# CONTROLSS_GLOBAL_CTRL_CONTROLSS_CTRL_502F0000h register map
Vendor: Texas Instruments
Peripheral module from a debugger description file (folder AM261x).
Registers are 32-bit, read-write, reset 0x0 unless marked. A register's access mark holds for its fields unless they carry their own. Offsets are as the file gives them; lines under a group give offsets from that group; [hi:lo] are bit positions; {n}, {i} and the like mark numbered series; 'fields as' and 'values as' point back to an identical list; <NAME> marks a mode.

## CONTROLSS_CTRL
{0x4+4i} CONTROLSS_CTRL_ADCEXTCHXBAR{i}_G0_SEL (i=0..9) — ADC EXTCH XBAR [x] Input Select.
  [3:0] ADCEXTCHXBAR{i}_G0_SEL_SEL — ADC EXTCH XBAR {i} Input Select0h ADC0 ADCCHSEL01h ADC0 ADCCHSEL12h ADC0 ADCCHSEL23h ADC0 ADCCHSEL34h ADC1 ADCCHSEL05h ADC1 ADCCHSEL16h ADC1 ADCCHSEL27h ADC1 ADCCHSEL38h ADC2 ADCCHSEL09h ADC2 ADCCHSEL1Ah: ADC2 ADCCHSEL2Bh: ADC2 ADCCHSEL3Example: ADC2EXTCHSEL_BIT0 needs to be connect to ADC_EXTCH_XBAROUT3, then ADCEXTCHXBAR3.G0.SEL set to 4'b1000
0x44 CONTROLSS_CTRL_ADCSOCFRCGBSEL — ADC Global SoC Force select.
  [2:0] ADCSOCFRCGBSEL_ENABLE — ADCSOCFRCGBSEL has one bit for each ADCBIT FIELD Descriptionbitx ADCx Indicate if ADCx selected for global SW trigger 1'b0 Not selected for Global SW Trigger 1'b1 Selected for Global SW TriggerReset Reset type: SYSRSnNote: x represents 0-2
0x48 CONTROLSS_CTRL_ADCSOCFRCGB — ADC Global SOC Force.
  [15:0] ADCSOCFRCGB_TRIG — ADCSOCFRCGB has one bit for each SOC[Start of conversion]BIT FIELD Descriptionbitxx SOCxx Indicate if SOCxx selected for global SW trigger 1'b0 Not selected for Global SW Trigger 1'b1 Selected for Global SW Trigger Reset type: SYSRSnNote: xx represents 0-15
0x4C CONTROLSS_CTRL_ADC_EXTCH_DLY_SEL reset 0x1 — Mux select to choose delay for adc_extchsel.
  [2:0] ADC_EXTCH_DLY_SEL_SEL — MUX select to choose delay3'd0: 2 cycle delay3'd1: 3 cycle delay3'd2: 4 cycle delay3'd3: 5 cycle delay3'd4: 6 cycle delay
0x78 CONTROLSS_CTRL_SDFM0_CLK0_OUT_SEL — SDFM0_CLK[x]_OUT Input Select.
  [0] SDFM0_CLK0_OUT_SEL_SEL — SDFM0_CLK0_OUT Input select 1'b0: ECAP0_OUT [default] 1'b1: ECAP7_OUT
0x7C CONTROLSS_CTRL_SDFM0_CLK1_OUT_SEL — SDFM0_CLK[x]_OUT Input Select.
  [0] SDFM0_CLK1_OUT_SEL_SEL — SDFM0_CLK1OUT Input select 1'b0: ECAP1_OUT [default] 1'b1: ECAP6_OUT
0x80 CONTROLSS_CTRL_SDFM0_CLK2_OUT_SEL — SDFM0_CLK[x]_OUT Input Select.
  [0] SDFM0_CLK2_OUT_SEL_SEL — SDFM0_CLK2_OUT Input select 1'b0: ECAP2_OUT [default] 1'b1: ECAP5_OUT
0x84 CONTROLSS_CTRL_SDFM0_CLK3_OUT_SEL — SDFM0_CLK[x]_OUT Input Select.
  [0] SDFM0_CLK3_OUT_SEL_SEL — SDFM0_CLK3_OUT Input select 1'b0: ECAP3_OUT [default] 1'b1: ECAP4_OUT
0x88 CONTROLSS_CTRL_SDFM1_CLK0_OUT_SEL — SDFM1_CLK[x]_OUT Input Select.
  [0] SDFM1_CLK0_OUT_SEL_SEL — SDFM1_CLK0_OUT Input select 1'b0: ECAP4_OUT [default] 1'b1: ECAP3_OUT
0x8C CONTROLSS_CTRL_SDFM1_CLK1_OUT_SEL — SDFM1_CLK[x]_OUT Input Select.
  [0] SDFM1_CLK1_OUT_SEL_SEL — SDFM1_CLK1_OUT Input select 1'b0: ECAP5_OUT [default] 1'b1: ECAP2_OUT
0x90 CONTROLSS_CTRL_SDFM1_CLK2_OUT_SEL — SDFM1_CLK[x]_OUT Input Select.
  [0] SDFM1_CLK2_OUT_SEL_SEL — SDFM1_CLK2_OUT Input select 1'b0: ECAP6_OUT [default] 1'b1: ECAP1_OUT
0x94 CONTROLSS_CTRL_SDFM1_CLK3_OUT_SEL — SDFM1_CLK[x]_OUT Input Select.
  [0] SDFM1_CLK3_OUT_SEL_SEL — SDFM1_CLK3_OUT Input select 1'b0: ECAP7_OUT [default] 1'b1: ECAP0_OUT
0xFC CONTROLSS_CTRL_SDFM1_CLK0_SEL — Sdfm1_clk0_sel.
  [0] SDFM1_CLK0_SEL_SEL — SDFM1 clock CK0 select1'b0: source is SDFM1 CK0 from Pinmux1'b1: source is SDFM0 CK0 from Pinmux
0x128 CONTROLSS_CTRL_CONTROLSS_G0_EPWM_WLINK — Enable for WLINK of EPWM groups.
  [31:0] CONTROLSS_G0_EPWM_WLINK_ENABLE — Writing 1'b1 enables the corresponding EPWM instance for WLINK feature
0x12C CONTROLSS_CTRL_CONTROLSS_G1_EPWM_WLINK — Enable for WLINK of EPWM groups.
  [31:0] CONTROLSS_G1_EPWM_WLINK_ENABLE — Writing 1'b1 enables the corresponding EPWM instance for WLINK feature
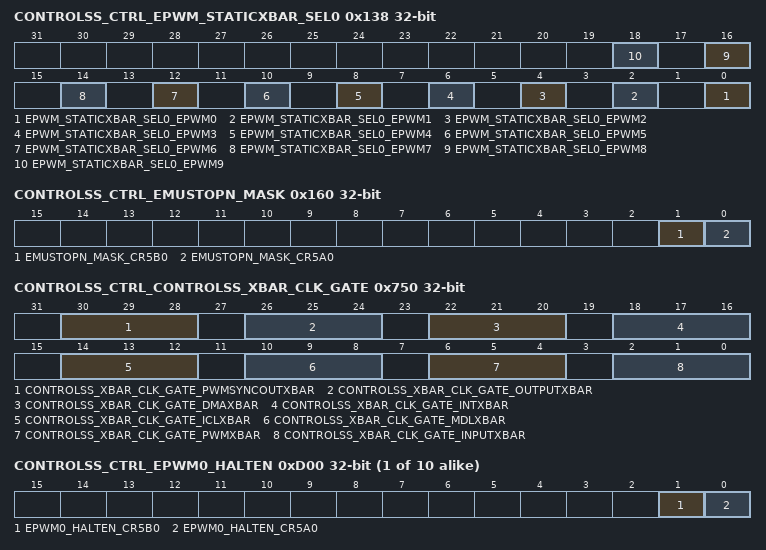
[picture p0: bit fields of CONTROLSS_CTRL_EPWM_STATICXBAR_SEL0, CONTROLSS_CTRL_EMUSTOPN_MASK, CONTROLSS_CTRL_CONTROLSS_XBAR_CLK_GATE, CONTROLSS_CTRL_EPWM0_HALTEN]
0x138 CONTROLSS_CTRL_EPWM_STATICXBAR_SEL0 — Static crossbar for epwm sel.
  [2n] EPWM_STATICXBAR_SEL0_EPWM{n} (n=0..9) — EPWM{n} access from PCR grouping - 00 = G0, 01 = G1
0x148 CONTROLSS_CTRL_EPWM_CLKSYNC — Epwm_clksync.
  [9:0] EPWM_CLKSYNC_BIT — EPWM clock sync for each EPWM instance. Set the bit corresponding to the instance number to enable that EPWM instance. When set, all enabled EPWM module clocks are started with the first rising edge of TBCLK aligned.Refer to TRM for more details.Writing 1'b1 will allow to enable corresponding EPWM instanceWriting 1'b0 will disable corresponding EPWM instance.
0x150 CONTROLSS_CTRL_EPWM_SOCA_SEL — Select line to choose EPWM SOC A to EQEPx.SOCA and PWMBAR.
  [9:0] EPWM_SOCA_SEL_SEL — MUX select to choose EPWM SOC A to EQEPx.SOCA and PWMBAR.Each bit in SOC_A_SEL corresponds to each inputEPWM_SOCA_SEL0:pwm_soca0EPWM_SOCA_SEL1:pwm_soca1EPWM_SOCA_SEL2:pwm_soca2EPWM_SOCA_SEL3:pwm_soca3EPWM_SOCA_SEL4:pwm_soca4EPWM_SOCA_SEL5:pwm_soca5EPWM_SOCA_SEL6:pwm_soca6EPWM_SOCA_SEL7:pwm_soca7EPWM_SOCA_SEL8:pwm_soca8EPWM_SOCA_SEL9:pwm_soca9
0x158 CONTROLSS_CTRL_EPWM_SOCB_SEL — Select line to choose EPWM SOC B to EQEPx.SOCB and PWMBAR.
  [9:0] EPWM_SOCB_SEL_SEL — MUX select to choose EPWM SOC B to EQEPx.SOCB and PWMBAR.Each bit in SOC_B_SEL corresponds to each inputEPWM_SOCB_SEL0:pwm_socb0EPWM_SOCB_SEL1:pwm_socb1EPWM_SOCB_SEL2:pwm_socb2EPWM_SOCB_SEL3:pwm_socb3EPWM_SOCB_SEL4:pwm_socb4EPWM_SOCB_SEL5:pwm_socb5EPWM_SOCB_SEL6:pwm_socb6EPWM_SOCB_SEL7:pwm_socb7EPWM_SOCB_SEL8:pwm_socb8EPWM_SOCB_SEL9:pwm_socb9
0x160 CONTROLSS_CTRL_EMUSTOPN_MASK — Emustopn_mask.
  [1] EMUSTOPN_MASK_CR5B0 — Bit-mask for debug suspend cpu cores to EPWM1'b0 R5FSS0_CORE1 enabled to control EMUSTOPn1'b1 R5FSS0_CORE1 disabled to control EMUSTOPn
  [0] EMUSTOPN_MASK_CR5A0 — Bit-mask for debug suspend cpu cores to EPWM1'b0 R5FSS0_CORE0 enabled to control EMUSTOPn1'b1 R5FSS0_CORE0 disabled to control EMUSTOPn
0x164 CONTROLSS_CTRL_CLB_AQ_EN0 — clb_aq_en0.
  [19:0] CLB_AQ_EN0_ENABLE — Enable ICCS control to CLB_AQ signal of PWM[9:0]
0x174 CONTROLSS_CTRL_CLB_DB_EN0 — clb_db_en0.
  [19:0] CLB_DB_EN0_ENABLE — Enable ICCS control to CLB_DB signal of PWM[9:0]
0x1AC CONTROLSS_CTRL_XBAR_LOOPBACK_CTRL — Mux select to enable Loopback for corresponding outputXBAR.
  [15:0] XBAR_LOOPBACK_CTRL_ENABLE — Mux select to enable Loopback for corresponding outputXBAR signal to the inputXBAR1'b0: Loopback disabled [default]1'b1: Loopback enable**Note: Each Mux select bit corresponds to the corresponding XBAR_LOOPBACK_CTRL_MUX
{0x200+4i} CONTROLSS_CTRL_EPWM{i}_CLK_GATE (i=0..9) — Epwm[x]_clk_gate.
  [2:0] EPWM{i}_CLK_GATE_CLK_GATE — Writing 3'b111 will gate clock for corresponding epwm
{0x300+4i} CONTROLSS_CTRL_ECAP{i}_CLK_GATE (i=0..7) — Ecap[x]_clk_gate.
  [2:0] ECAP{i}_CLK_GATE_CLK_GATE — Writing 3'b111 will gate clock for corresponding ecap
{0x400+4i} CONTROLSS_CTRL_CMPSSA{i}_CLK_GATE (i=0..8) — cmpssa[x]_clk_gate.
  [2:0] CMPSSA{i}_CLK_GATE_CLK_GATE — Writing 3'b111 will gate clock for corresponding cmpssa
{0x480+4i} CONTROLSS_CTRL_ADC_SCTILE{i}_CLK_GATE (i=0..5) — ADC Safecheck tiles clock gate.
  [2:0] ADC_SCTILE{i}_CLK_GATE_CLK_GATE — Writing 3'b111 will gate clock for corresponding adc safety tiles
{0x540+4i} CONTROLSS_CTRL_ADC{i}_CLK_GATE (i=0..2) — Adc[x]_clk_gate.
  [2:0] ADC{i}_CLK_GATE_CLK_GATE — Writing 3'b111 will gate clock for corresponding adc
0x5A0 CONTROLSS_CTRL_EQEP0_CLK_GATE — Eqep[x]_clk_gate.
  [2:0] EQEP0_CLK_GATE_CLK_GATE — Writing 3'b111 will gate clock for corresponding eqep
0x5A4 CONTROLSS_CTRL_EQEP1_CLK_GATE — Eqep[x]_clk_gate.
  [2:0] EQEP1_CLK_GATE_CLK_GATE — Writing 3'b111 will gate clock for corresponding eqep
0x5C0 CONTROLSS_CTRL_SDFM0_CLK_GATE — Sdfm[x]_clk_gate.
  [2:0] SDFM0_CLK_GATE_CLK_GATE — Writing 3'b111 will gate clock for corresponding sdfm
0x5C4 CONTROLSS_CTRL_SDFM1_CLK_GATE — Sdfm[x]_clk_gate.
  [2:0] SDFM1_CLK_GATE_CLK_GATE — Writing 3'b111 will gate clock for corresponding sdfm
0x5E0 CONTROLSS_CTRL_OTTO0_CLK_GATE — Otto[x]_clk_gate.
  [2:0] OTTO0_CLK_GATE_CLK_GATE — Writing 3'b111 will gate clock for corresponding otto
0x5E4 CONTROLSS_CTRL_OTTO1_CLK_GATE — Otto[x]_clk_gate.
  [2:0] OTTO1_CLK_GATE_CLK_GATE — Writing 3'b111 will gate clock for corresponding otto
0x600 CONTROLSS_CTRL_FSI_TX0_CLK_GATE — fsi_tx[x]_clk_gate.
  [2:0] FSI_TX0_CLK_GATE_CLK_GATE — Writing 3'b111 will gate clock for corresponding fsi_tx
0x620 CONTROLSS_CTRL_FSI_RX0_CLK_GATE — fsi_rx[x]_clk_gate.
  [2:0] FSI_RX0_CLK_GATE_CLK_GATE — Writing 3'b111 will gate clock for corresponding fsi_rx
0x680 CONTROLSS_CTRL_ADC_AGG0_CLK_GATE — ADC Aggregator clock gate.
  [2:0] ADC_AGG0_CLK_GATE_CLK_GATE — Writing 3'b111 will gate clock for corresponding adc aggregator
0x690 CONTROLSS_CTRL_DAC_CLK_GATE — dac_clk_gate.
  [2:0] DAC_CLK_GATE_CLK_GATE — Writing 3'b111 will gate clock for dac
0x6F0 CONTROLSS_CTRL_FSI_TX0_PLL_CLK_GATE — fsi_tx[x]_pll_clk_gate.
  [2:0] FSI_TX0_PLL_CLK_GATE_CLK_GATE — Writing 3'b111 will gate clock for corresponding fsi rx pll clock
0x710 CONTROLSS_CTRL_SDFM0_PLL_CLK_GATE — Sdfm[x]_pll_clk_gate.
  [2:0] SDFM0_PLL_CLK_GATE_CLK_GATE — Writing 3'b111 will gate clock for corresponding sdfm pll clock
0x714 CONTROLSS_CTRL_SDFM1_PLL_CLK_GATE — Sdfm[x]_pll_clk_gate.
  [2:0] SDFM1_PLL_CLK_GATE_CLK_GATE — Writing 3'b111 will gate clock for corresponding sdfm pll clock
0x750 CONTROLSS_CTRL_CONTROLSS_XBAR_CLK_GATE — clock gate for eight XBARs.
  [30:28] CONTROLSS_XBAR_CLK_GATE_PWMSYNCOUTXBAR — Writing 3'b111 to register will clock gate the corresponding XBAR
  [26:24] CONTROLSS_XBAR_CLK_GATE_OUTPUTXBAR — Writing 3'b111 to register will clock gate the corresponding XBAR
  [22:20] CONTROLSS_XBAR_CLK_GATE_DMAXBAR — Writing 3'b111 to register will clock gate the corresponding XBAR
  [18:16] CONTROLSS_XBAR_CLK_GATE_INTXBAR — Writing 3'b111 to register will clock gate the corresponding XBAR
  [14:12] CONTROLSS_XBAR_CLK_GATE_ICLXBAR — Writing 3'b111 to register will clock gate the corresponding XBAR
  [10:8] CONTROLSS_XBAR_CLK_GATE_MDLXBAR — Writing 3'b111 to register will clock gate the corresponding XBAR
  [6:4] CONTROLSS_XBAR_CLK_GATE_PWMXBAR — Writing 3'b111 to register will clock gate the corresponding XBAR
  [2:0] CONTROLSS_XBAR_CLK_GATE_INPUTXBAR — Writing 3'b111 to register will clock gate the corresponding XBAR
{0x800+4i} CONTROLSS_CTRL_EPWM{i}_RST (i=0..9) — Epwm[x]_rst.
  [2:0] EPWM{i}_RST_RST — Writing 3'b111 will generate reset for corresponding epwm
{0x900+4i} CONTROLSS_CTRL_ECAP{i}_RST (i=0..7) — Ecap[x]_rst.
  [2:0] ECAP{i}_RST_RST — Writing 3'b111 will generate reset for corresponding ecap
{0xA00+4i} CONTROLSS_CTRL_CMPSSA{i}_RST (i=0..8) — cmpssa[x]_rst.
  [2:0] CMPSSA{i}_RST_RST — Writing 3'b111 will generate reset for corresponding cmpssa
{0xA80+4i} CONTROLSS_CTRL_ADC_SCTILE{i}_RST (i=0..5) — ADC Safecheck tiles Reset.
  [2:0] ADC_SCTILE{i}_RST_RST — Writing 3'b111 will generate reset for corresponding adc safety tiles
{0xB40+4i} CONTROLSS_CTRL_ADC{i}_RST (i=0..2) — Adc[x]_rst.
  [2:0] ADC{i}_RST_RST — Writing 3'b111 will generate reset for corresponding adc
0xBA0 CONTROLSS_CTRL_EQEP0_RST — Eqep[x]_rst.
  [2:0] EQEP0_RST_RST — Writing 3'b111 will generate reset for corresponding eqep
0xBA4 CONTROLSS_CTRL_EQEP1_RST — Eqep[x]_rst.
  [2:0] EQEP1_RST_RST — Writing 3'b111 will generate reset for corresponding eqep
0xBC0 CONTROLSS_CTRL_SDFM0_RST — Sdfm[x]_rst.
  [2:0] SDFM0_RST_RST — Writing 3'b111 will generate reset for corresponding sdfm
0xBC4 CONTROLSS_CTRL_SDFM1_RST — Sdfm[x]_rst.
  [2:0] SDFM1_RST_RST — Writing 3'b111 will generate reset for corresponding sdfm
0xBE0 CONTROLSS_CTRL_OTTO0_RST — Otto[x]_rst.
  [2:0] OTTO0_RST_RST — Writing 3'b111 will generate reset for corresponding otto
0xBE4 CONTROLSS_CTRL_OTTO1_RST — Otto[x]_rst.
  [2:0] OTTO1_RST_RST — Writing 3'b111 will generate reset for corresponding otto
0xC00 CONTROLSS_CTRL_FSI_TX0_RST — fsi_tx[x]_rst.
  [2:0] FSI_TX0_RST_RST — Writing 3'b111 will generate reset for corresponding fsi_tx
0xC20 CONTROLSS_CTRL_FSI_RX0_RST — fsi_rx[x]_rst.
  [2:0] FSI_RX0_RST_RST — Writing 3'b111 will generate reset for corresponding fsi_rx
0xC80 CONTROLSS_CTRL_ADC_AGG0_RST — ADC Aggregator Reset.
  [2:0] ADC_AGG0_RST_RST — Writing 3'b111 will generate reset for corresponding adc aggregator
0xC90 CONTROLSS_CTRL_DAC_RST — dac_rst.
  [2:0] DAC_RST_RST — Writing 3'b111 will generate reset for dac
{0xD00+4i} CONTROLSS_CTRL_EPWM{i}_HALTEN (i=0..9) — Epwm halten.
  [1] EPWM{i}_HALTEN_CR5B0 — 1'b0: IP Halt disabled with corresponding CPU halt1'b1: IP Halt enabled with corresponding CPU halt
  [0] EPWM{i}_HALTEN_CR5A0 — 1'b0: IP Halt disabled with corresponding CPU halt1'b1: IP Halt enabled with corresponding CPU halt
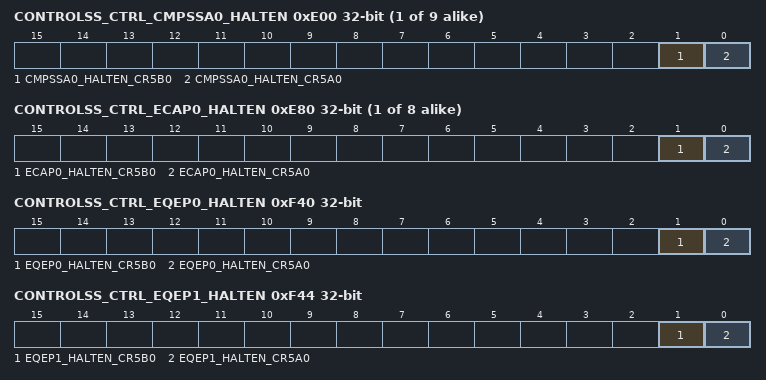
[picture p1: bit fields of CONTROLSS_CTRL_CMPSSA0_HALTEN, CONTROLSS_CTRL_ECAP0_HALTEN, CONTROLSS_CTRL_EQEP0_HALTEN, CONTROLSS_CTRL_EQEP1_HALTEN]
{0xE00+4i} CONTROLSS_CTRL_CMPSSA{i}_HALTEN (i=0..8) — cmpssa halten.
  [1] CMPSSA{i}_HALTEN_CR5B0 — 1'b0: IP Halt disabled with corresponding CPU halt1'b1: IP Halt enabled with corresponding CPU halt
  [0] CMPSSA{i}_HALTEN_CR5A0 — 1'b0: IP Halt disabled with corresponding CPU halt1'b1: IP Halt enabled with corresponding CPU halt
{0xE80+4i} CONTROLSS_CTRL_ECAP{i}_HALTEN (i=0..7) — Ecap halten.
  [1] ECAP{i}_HALTEN_CR5B0 — 1'b0: IP Halt disabled with corresponding CPU halt1'b1: IP Halt enabled with corresponding CPU halt
  [0] ECAP{i}_HALTEN_CR5A0 — 1'b0: IP Halt disabled with corresponding CPU halt1'b1: IP Halt enabled with corresponding CPU halt
0xF40 CONTROLSS_CTRL_EQEP0_HALTEN — Eqep halten.
  [1] EQEP0_HALTEN_CR5B0 — 1'b0: IP Halt disabled with corresponding CPU halt1'b1: IP Halt enabled with corresponding CPU halt
  [0] EQEP0_HALTEN_CR5A0 — 1'b0: IP Halt disabled with corresponding CPU halt1'b1: IP Halt enabled with corresponding CPU halt
0xF44 CONTROLSS_CTRL_EQEP1_HALTEN — Eqep halten.
  [1] EQEP1_HALTEN_CR5B0 — 1'b0: IP Halt disabled with corresponding CPU halt1'b1: IP Halt enabled with corresponding CPU halt
  [0] EQEP1_HALTEN_CR5A0 — 1'b0: IP Halt disabled with corresponding CPU halt1'b1: IP Halt enabled with corresponding CPU halt
0x1008 CONTROLSS_CTRL_LOCK0_KICK0 — - KICK0 component.
  [31:0] LOCK0_KICK0 — - KICK0 component
0x100C CONTROLSS_CTRL_LOCK0_KICK1 — - KICK1 component.
  [31:0] LOCK0_KICK1 — - KICK1 component
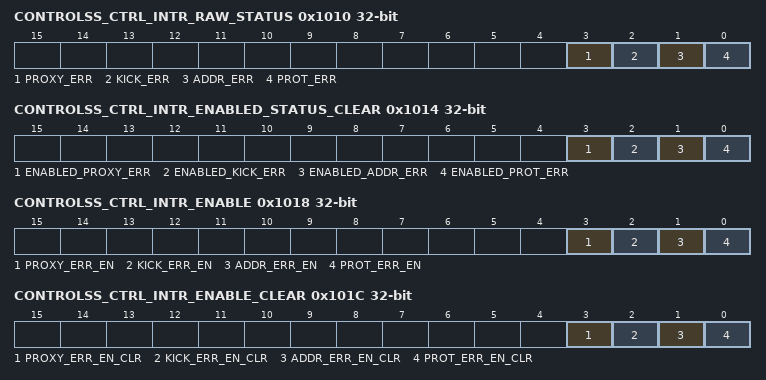
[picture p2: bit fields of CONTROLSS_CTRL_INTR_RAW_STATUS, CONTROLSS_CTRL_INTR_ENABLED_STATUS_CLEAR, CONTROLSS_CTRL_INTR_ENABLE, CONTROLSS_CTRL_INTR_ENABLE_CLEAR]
0x1010 CONTROLSS_CTRL_INTR_RAW_STATUS access not given — Interrupt Raw Status/Set Register.
  [3] PROXY_ERR — Proxy0 access violation error. Raw status is read. Write a 1 to set the status. Writing a 0 has no effect. (access R/W1TS)
  [2] KICK_ERR — Kick access violation error. Raw status is read. Write a 1 to set the status. Writing a 0 has no effect. (access R/W1TS)
  [1] ADDR_ERR — Addressing violation error. Raw status is read. Write a 1 to set the status. Writing a 0 has no effect. (access R/W1TS)
  [0] PROT_ERR — Protection violation error. Raw status is read. Write a 1 to set the status. Writing a 0 has no effect. (access R/W1TS)
0x1014 CONTROLSS_CTRL_INTR_ENABLED_STATUS_CLEAR access not given — Interrupt Enabled Status/Clear register.
  [3] ENABLED_PROXY_ERR — Proxy0 access violation error. Enabled status is read. Write a 1 to clear the status. Writing a 0 has no effect. (access R/W1TC)
  [2] ENABLED_KICK_ERR — Kick access violation error. Enabled status is read. Write a 1 to clear the status. Writing a 0 has no effect. (access R/W1TC)
  [1] ENABLED_ADDR_ERR — Addressing violation error. Enabled status is read. Write a 1 to clear the status. Writing a 0 has no effect. (access R/W1TC)
  [0] ENABLED_PROT_ERR — Protection violation error. Enabled status is read. Write a 1 to clear the status. Writing a 0 has no effect. (access R/W1TC)
0x1018 CONTROLSS_CTRL_INTR_ENABLE access not given — Interrupt Enable register.
  [3] PROXY_ERR_EN — Proxy0 access violation error enable. Write a 1 to set the enable. Writing a 0 has no effect. (access R/W1TS)
  [2] KICK_ERR_EN — Kick access violation error enable. Write a 1 to set the enable. Writing a 0 has no effect. (access R/W1TS)
  [1] ADDR_ERR_EN — Addressing violation error enable. Write a 1 to set the enable. Writing a 0 has no effect. (access R/W1TS)
  [0] PROT_ERR_EN — Protection violation error enable. Write a 1 to set the enable. Writing a 0 has no effect. (access R/W1TS)
0x101C CONTROLSS_CTRL_INTR_ENABLE_CLEAR access not given — Interrupt Enable Clear register.
  [3] PROXY_ERR_EN_CLR — Proxy0 access violation error enable clear. Write a 1 to clear the enable. Writing a 0 has no effect. (access R/W1TC)
  [2] KICK_ERR_EN_CLR — Kick access violation error enable clear. Write a 1 to clear the enable. Writing a 0 has no effect. (access R/W1TC)
  [1] ADDR_ERR_EN_CLR — Addressing violation error enable clear. Write a 1 to clear the enable. Writing a 0 has no effect. (access R/W1TC)
  [0] PROT_ERR_EN_CLR — Protection violation error enable clear. Write a 1 to clear the enable. Writing a 0 has no effect. (access R/W1TC)
0x1020 CONTROLSS_CTRL_EOI — EOI register.
  [7:0] EOI_VECTOR — EOI vector value. Write this with interrupt distribution value in the chip.
0x1024 CONTROLSS_CTRL_FAULT_ADDRESS ro — Fault Address register.
  [31:0] FAULT_ADDR — Fault Address.
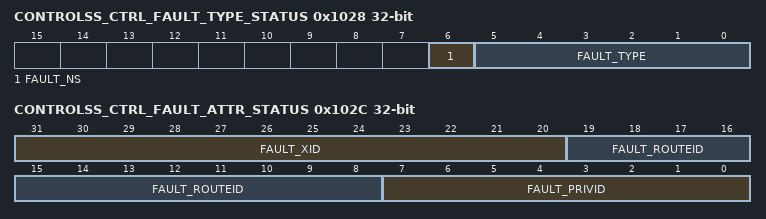
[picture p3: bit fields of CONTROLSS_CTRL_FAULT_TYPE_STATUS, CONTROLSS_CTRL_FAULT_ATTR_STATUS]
0x1028 CONTROLSS_CTRL_FAULT_TYPE_STATUS ro — Fault Type Status register.
  [6] FAULT_NS — Non-secure access.
  [5:0] FAULT_TYPE — Fault Type 10_0000 = Supervisor read fault - priv = 1 dir = 1 dtype != 1 01_0000 = Supervisor write fault - priv = 1 dir = 0 00_1000 = Supervisor execute fault - priv = 1 dir = 1 dtype = 1 00_0100 = User read fault - priv = 0 dir = 1 dtype = 1 00_0010 = User write fault - priv = 0 dir = 0 00_0001 = User execute fault - priv = 0 dir = 1 dtype = 1 00_0000 = No fault
0x102C CONTROLSS_CTRL_FAULT_ATTR_STATUS ro — Fault Attribute Status register.
  [31:20] FAULT_XID — XID.
  [19:8] FAULT_ROUTEID — Route ID.
  [7:0] FAULT_PRIVID — Privilege ID.
0x1030 CONTROLSS_CTRL_FAULT_CLEAR wo — Fault Clear register.
  [0] FAULT_CLR — Fault clear. Writing a 1 clears the current fault. Writing a 0 has no effect.
